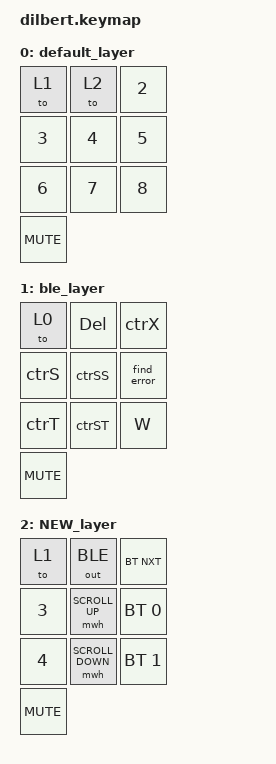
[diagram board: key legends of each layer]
#include <behaviors.dtsi>
#include <dt-bindings/zmk/keys.h>
#include <dt-bindings/zmk/mouse.h>
#include <dt-bindings/zmk/bt.h>
#include <dt-bindings/zmk/outputs.h>

#define DEFAULT 0
#define BLE 1
#define NEW 2
#define NONE 0

#define U_MOUSE_MOVE_MAX 1400                     /* <--- New max speed setting (default: 600) */
#define MOVE_UP MOVE_VERT(-U_MOUSE_MOVE_MAX)
#define MOVE_DOWN MOVE_VERT(U_MOUSE_MOVE_MAX)
#define MOVE_LEFT MOVE_HOR(-U_MOUSE_MOVE_MAX)
#define MOVE_RIGHT MOVE_HOR(U_MOUSE_MOVE_MAX)

&mmv {
	time-to-max-speed-ms = <400>;             /* <--- How long time until max speed is reached (default: 500) */
};

#define U_MOUSE_SCROLL_MAX 100                    /* <--- New max speed setting (default: 10) */
#define SCROLL_UP SCROLL_VERT(U_MOUSE_SCROLL_MAX)
#define SCROLL_DOWN SCROLL_VERT(-U_MOUSE_SCROLL_MAX)
#define SCROLL_LEFT SCROLL_HOR(-U_MOUSE_SCROLL_MAX)
#define SCROLL_RIGHT SCROLL_HOR(U_MOUSE_SCROLL_MAX)

&mwh {
  time-to-max-speed-ms = <500>;                 /* <--- How long time until max speed is reached */
};

/ {

  behaviors {
        pht: positional_hold_tap {
            compatible = "zmk,behavior-hold-tap";
            label = "POSITIONAL_HOLD_TAP";
            #binding-cells = <2>;
            flavor = "hold-preferred";
            tapping-term-ms = <400>;
            quick-tap-ms = <200>;
            bindings = <&kp>, <&kp>;
            hold-trigger-key-positions = <1>;    // <---[[the W key]]
        };

        lh_pht: left_hand_positional_hold_tap {
            compatible = "zmk,behavior-hold-tap";
            label = "LEFT_POSITIONAL_HOLD_TAP";
            #binding-cells = <2>;
            flavor = "tap-unless-interrupted";
            tapping-term-ms = <100>;                        // <---[[produces tap if held longer than tapping-term-ms]]
            quick-tap-ms = <200>;
            bindings = <&kp>, <&kp>;
            hold-trigger-key-positions = <5 6 7 8 9 10>;    // <---[[right-hand keys]]
        };

        hm: homerow_mods {
            compatible = "zmk,behavior-hold-tap";
            label = "HOMEROW_MODS";
            #binding-cells = <2>;
            tapping-term-ms = <150>;
            quick-tap-ms = <0>;
            flavor = "tap-preferred";
            bindings = <&kp>, <&kp>;
        };

        bhm: balanced_homerow_mods {
            compatible = "zmk,behavior-hold-tap";
            label = "HOMEROW_MODS";
            #binding-cells = <2>;
            tapping-term-ms = <200>;    // <---[[moderate duration]]
            quick-tap-ms = <0>;
            flavor = "balanced";
            bindings = <&kp>, <&kp>;
        };
  };

  macros {
    ctrA: ctrA {
      label = "ctrA";
      compatible = "zmk,behavior-macro";
      #binding-cells = <0>;
      bindings =  <&macro_press &kp LCTRL>,
                  <&macro_tap &kp A>,
                  <&macro_release &kp LCTRL>;
    };

    ctrX: ctrX {
      label = "ctrX";
      compatible = "zmk,behavior-macro";
      #binding-cells = <0>;
      bindings =  <&macro_press &kp LCTRL>,
                  <&macro_tap &kp X>,
                  <&macro_release &kp LCTRL>;
    };

    ctrS: ctrS {
      label = "ctrS";
      compatible = "zmk,behavior-macro";
      #binding-cells = <0>;
      bindings =  <&macro_press &kp LCTRL>,
                  <&macro_tap &kp S>,
                  <&macro_release &kp LCTRL>;
    };

    ctrSS: ctrSS {
      label = "ctrSS";
      compatible = "zmk,behavior-macro";
      #binding-cells = <0>;
      bindings =  <&macro_press &kp LCTRL &kp LEFT_SHIFT>,
                  <&macro_tap &kp S>,
                  <&macro_release &kp LCTRL &kp LEFT_SHIFT>;
    };

    ctrT: ctrT {
      label = "ctrT";
      compatible = "zmk,behavior-macro";
      #binding-cells = <0>;
      bindings =  <&macro_press &kp LCTRL>,
                  <&macro_tap &kp T>,
                  <&macro_release &kp LCTRL>;
    };

    ctrST: ctrST {
      label = "ctrST";
      compatible = "zmk,behavior-macro";
      #binding-cells = <0>;
      bindings =  <&macro_press &kp LCTRL &kp LEFT_SHIFT>,
                  <&macro_tap &kp T>,
                  <&macro_release &kp LCTRL &kp LEFT_SHIFT>;
    };

    find_error: find_error {
      label = "find_error";
      compatible = "zmk,behavior-macro";
      #binding-cells = <0>;
      bindings =  <&macro_press &kp LCTRL>,
                  <&macro_tap &kp F>,
                  <&macro_release &kp LCTRL>,
                  <&macro_wait_time 500>,
                  <&macro_tap &kp E &kp R &kp R &kp O &kp R>;

    };
  };

  keymap {
    compatible = "zmk,keymap";

    default_layer {
      bindings = <
        &to 1               &to 2    &kp NUMBER_2 
        &kp NUMBER_3    &kp NUMBER_4    &kp NUMBER_5    
        &kp NUMBER_6        &kp NUMBER_7    &kp NUMBER_8  
        &kp C_MUTE               
      >;
     sensor-bindings = <&inc_dec_kp C_VOLUME_UP C_VOLUME_DOWN>;
    };

    ble_layer {
      bindings = <
        &to 0            &kp DEL             &ctrX
        &ctrS            &ctrSS              &find_error  
        &ctrT            &ctrST              &kp W 
        &kp C_MUTE      
     >;
      sensor-bindings = <&inc_dec_kp PAGE_UP PAGE_DOWN>;
    };

    NEW_layer {
      bindings = <
        &to 1               &out OUT_BLE        &bt BT_NXT 
        &kp NUMBER_3        &mwh SCROLL_UP      &bt BT_SEL 0    
        &kp NUMBER_4        &mwh SCROLL_DOWN    &bt BT_SEL 1  
        &kp C_MUTE               
      >;
      sensor-bindings = <&inc_dec_kp PAGE_UP PAGE_DOWN>;
    };
    
  };


};
